# f28003x_dcsm_common_regs register map
Vendor: Texas Instruments
Peripheral module from a debugger description file (folder C2000).
Address unit: 16 bits
Registers are 32-bit, read-only, no defined reset value unless marked. A register's access mark holds for its fields unless they carry their own. Offsets are as the file gives them; lines under a group give offsets from that group; [hi:lo] are bit positions; {n}, {i} and the like mark numbered series; 'fields as' and 'values as' point back to an identical list; <NAME> marks a mode.

## DCSM_COMMON_REGS — DCSM COMMON Registers
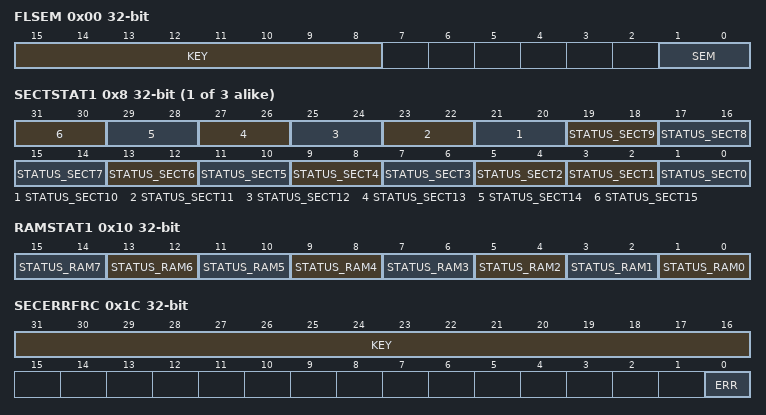
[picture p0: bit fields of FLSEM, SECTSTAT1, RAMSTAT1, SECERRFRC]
0x00 FLSEM rw — Flash Wrapper Semaphore Register
  [15:8] KEY — Semaphore Key
  [1:0] SEM — Flash Semaphore Bit
{0x6+2i} SECTSTAT{i} (i=1..3) — Flash Sectors Status Register {i}
  [2n+1:2n] STATUS_SECT{n} (n=9..15) — Zone Status flash Bank {i-1} Sector {n}
  [17:16] STATUS_SECT8 — Zone Status flash Bank {i-1} sector 8
  [2n+1:2n] STATUS_SECT{n} (n=2..7) — Zone Status flash Bank {i-1} Sector {n}
  [3:2] STATUS_SECT1 — Zone Status flash Bank {i-1} sector 1
  [1:0] STATUS_SECT0 — Zone Status flash Bank {i-1} Sector 0
0x10 RAMSTAT1 — RAM Status Register 1
  [2n+1:2n] STATUS_RAM{n} (n=0..7) — Zone Status RAM LS{n}
0x18 SECERRSTAT — Security Error Status Register
  [0] ERR — Security Configuration load Error Status
0x1A SECERRCLR rw — Security Error Clear Register
  [0] ERR — Clear Security Configuration Load Error Status Bit
0x1C SECERRFRC rw — Security Error Force Register
  [31:16] KEY — Valid Register Write Key
  [0] ERR — Set Security Configuration Load Error Status Bit
